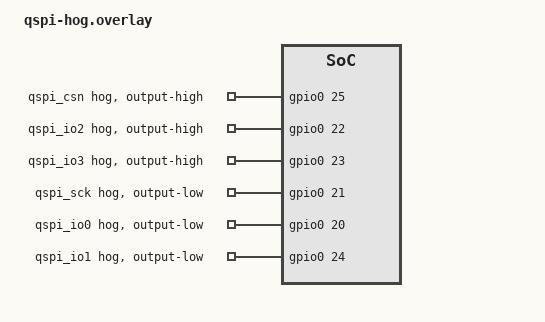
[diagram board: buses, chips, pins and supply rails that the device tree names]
/* power-bisect only: the QSPI flash is unused (NORDIC_QSPI_NOR=n), so its
 * pins would otherwise float. Drive them to defined idle levels: chip
 * deselected (CSN high), WP#/HOLD# high, clock and data low. GPIO output
 * levels persist into System OFF. */
&qspi { status = "disabled"; };
&gpio0 {
    qspi_csn  { gpio-hog; gpios = <25 GPIO_ACTIVE_HIGH>; output-high; };
    qspi_io2  { gpio-hog; gpios = <22 GPIO_ACTIVE_HIGH>; output-high; };
    qspi_io3  { gpio-hog; gpios = <23 GPIO_ACTIVE_HIGH>; output-high; };
    qspi_sck  { gpio-hog; gpios = <21 GPIO_ACTIVE_HIGH>; output-low; };
    qspi_io0  { gpio-hog; gpios = <20 GPIO_ACTIVE_HIGH>; output-low; };
    qspi_io1  { gpio-hog; gpios = <24 GPIO_ACTIVE_HIGH>; output-low; };
};
